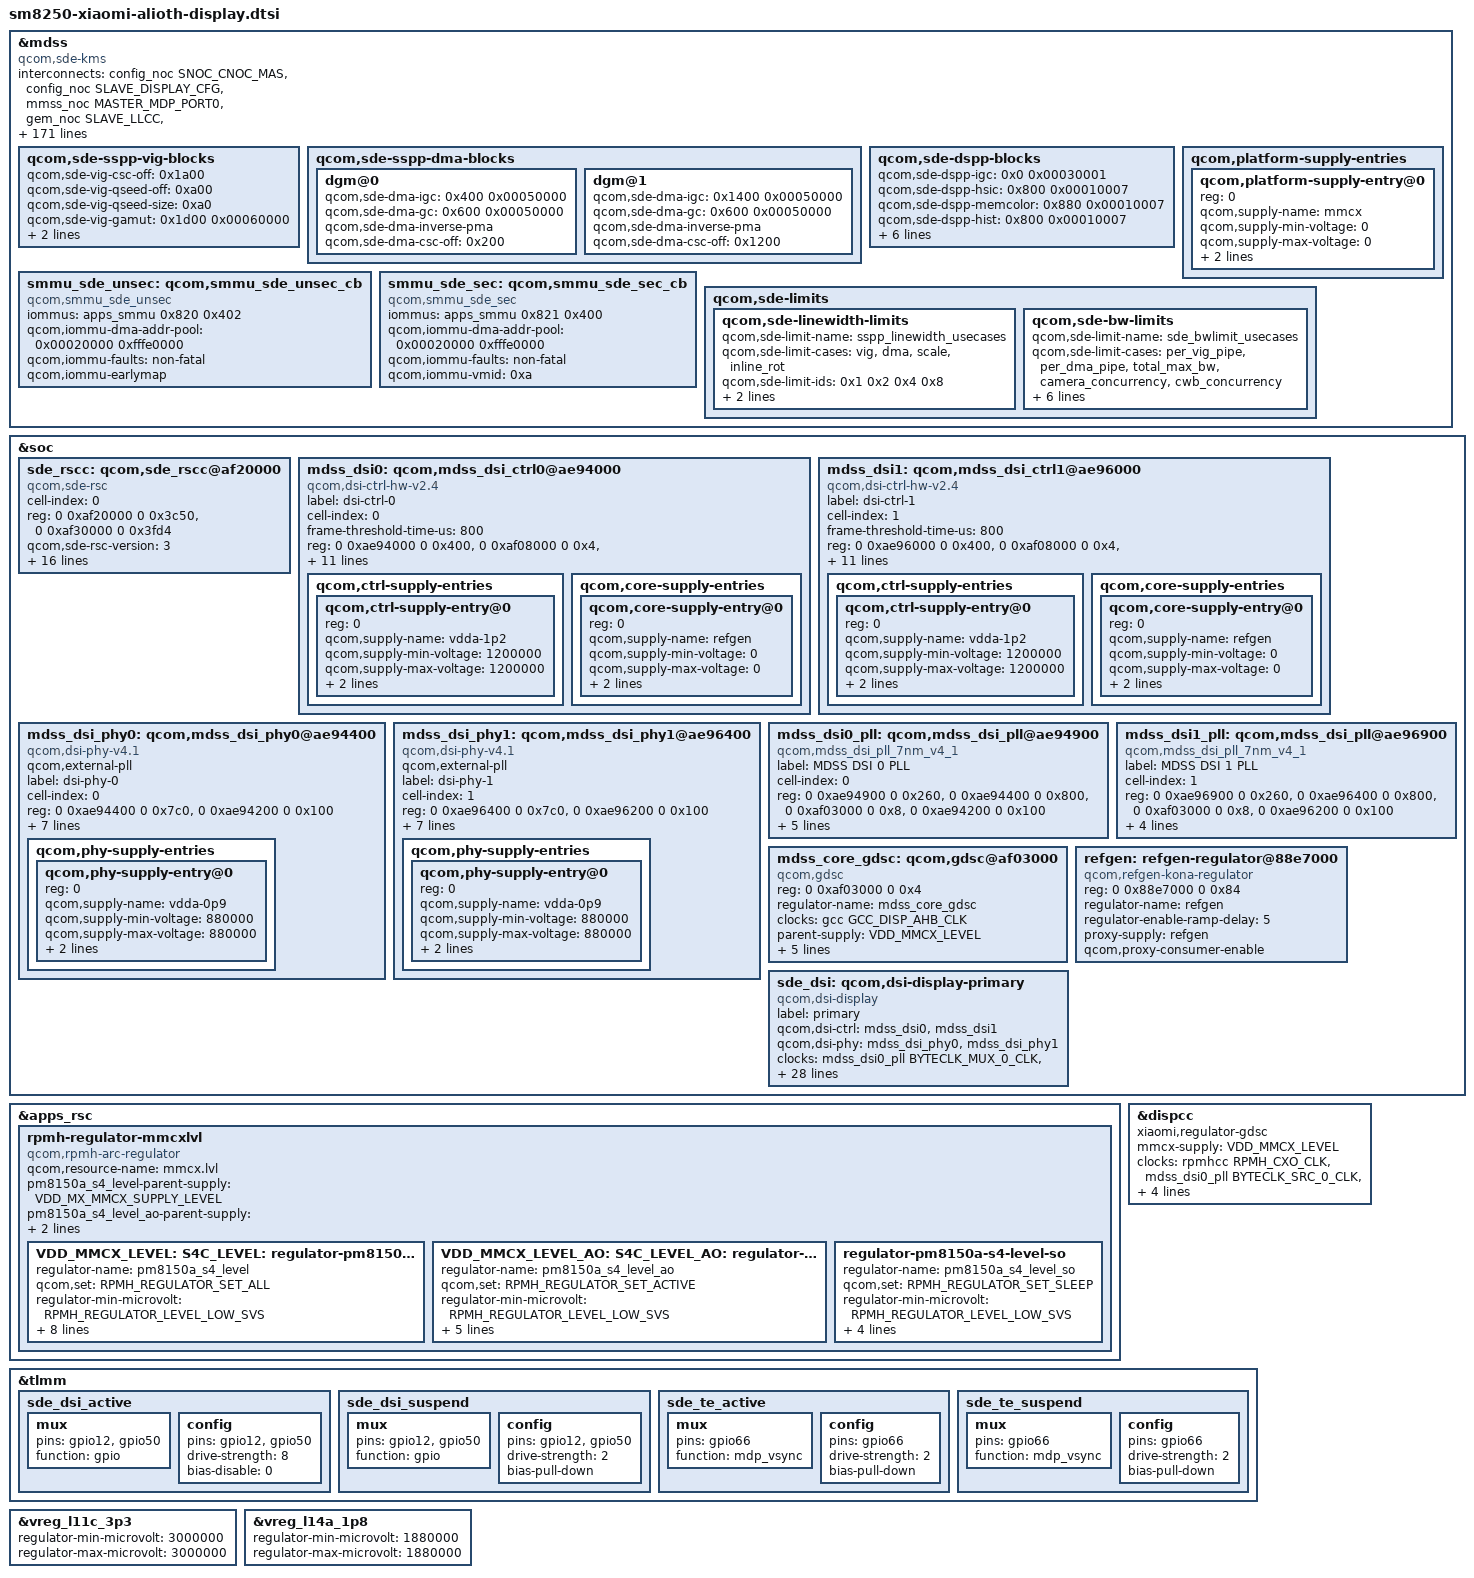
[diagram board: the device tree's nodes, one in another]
// SPDX-License-Identifier: GPL-2.0-only
/* Donor SDE catalog, translated native clocks and interconnect providers. */
#include <dt-bindings/clock/mdss-7nm-pll-clk.h>
#include <dt-bindings/interconnect/qcom,sm8250.h>


&mdss {
 /delete-property/ power-domains;
 status = "okay";

 interconnects = <&config_noc SNOC_CNOC_MAS &config_noc SLAVE_DISPLAY_CFG>,
  <&mmss_noc MASTER_MDP_PORT0 &gem_noc SLAVE_LLCC>,
  <&mmss_noc MASTER_MDP_PORT1 &gem_noc SLAVE_LLCC>,
  <&gem_noc MASTER_MNOC_HF_MEM_NOC &gem_noc SLAVE_LLCC>,
  <&mc_virt MASTER_LLCC &mc_virt SLAVE_EBI_CH0>;
 interconnect-names = "qcom,sde-reg-bus", "qcom,sde-data-bus0",
  "qcom,sde-data-bus1", "qcom,sde-llcc-bus", "qcom,sde-ebi-bus";
 qcom,sde-reg-bus,vectors-KBps = <0 0>, <0 76800>, <0 150000>, <0 300000>;
 connectors = <&sde_dsi &sde_rscc>;

};

&mdss {
 /delete-node/ mdp@ae01000;
 /delete-node/ dsi@ae94000;
 /delete-node/ dsi@ae96000;
 /delete-node/ dsi-phy@ae94400;
 /delete-node/ dsi-phy@ae96400;
};

&mdss {

		compatible = "qcom,sde-kms";
		reg = <0 0x0ae00000 0 0x84208>,
		      <0 0x0aeb0000 0 0x2008>,
		      <0 0x0aeac000 0 0x214>,
		      <0 0x0ae8f000 0 0x02c>,
		      <0 0x0af50000 0 0x038>;
		reg-names = "mdp_phys",
			"vbif_phys",
			"regdma_phys",
			"sid_phys",
			"swfuse_phys";

		clocks =
			<&gcc GCC_DISP_AHB_CLK>,
			<&gcc GCC_DISP_HF_AXI_CLK>,
			<&gcc GCC_DISP_SF_AXI_CLK>,
			<&dispcc DISP_CC_MDSS_AHB_CLK>,
			<&dispcc DISP_CC_MDSS_MDP_CLK>,
			<&dispcc DISP_CC_MDSS_VSYNC_CLK>,
			<&dispcc DISP_CC_MDSS_MDP_LUT_CLK>,
			<&dispcc DISP_CC_MDSS_ROT_CLK>;
		clock-names = "gcc_iface", "gcc_bus", "gcc_nrt_bus",
				"iface_clk", "core_clk", "vsync_clk",
				"lut_clk", "rot_clk";
		clock-rate = <0 0 0 0 300000000 19200000 300000000 19200000>;
		clock-max-rate = <0 0 0 0 460000000 19200000 460000000
					460000000>;

		mmcx-supply = <&VDD_MMCX_LEVEL>;

		/* interrupt config */
		interrupts = <GIC_SPI 83 IRQ_TYPE_LEVEL_HIGH>;
		interrupt-controller;
		#interrupt-cells = <1>;

		#power-domain-cells = <0>;

		/* hw blocks */
		qcom,sde-off = <0x1000>;
		qcom,sde-len = <0x494>;

		qcom,sde-ctl-off = <0x2000 0x2200 0x2400
				     0x2600 0x2800 0x2a00>;
		qcom,sde-ctl-size = <0x1dc>;
		qcom,sde-ctl-display-pref = "primary", "none", "none",
			    "none", "none";

		qcom,sde-mixer-off = <0x45000 0x46000 0x47000
				      0x48000 0x49000 0x4a000>;
		qcom,sde-mixer-size = <0x320>;
		qcom,sde-mixer-display-pref = "primary", "primary", "none",
					      "none", "none", "none";

		qcom,sde-mixer-cwb-pref = "none", "none", "cwb",
					      "cwb", "cwb", "cwb";

		qcom,sde-dspp-top-off = <0x1300>;
		qcom,sde-dspp-top-size = <0x80>;
		qcom,sde-dspp-off = <0x55000 0x57000 0x59000 0x5b000>;
		qcom,sde-dspp-size = <0x1800>;

		qcom,sde-dest-scaler-top-off = <0x00061000>;
		qcom,sde-dest-scaler-top-size = <0x1c>;
		qcom,sde-dest-scaler-off = <0x800 0x1000>;
		qcom,sde-dest-scaler-size = <0x800>;

		qcom,sde-wb-off = <0x66000>;
		qcom,sde-wb-size = <0x2c8>;
		qcom,sde-wb-xin-id = <6>;
		qcom,sde-wb-id = <2>;
		qcom,sde-wb-clk-ctrl = <0x2bc 16>;
		qcom,sde-wb-clk-status = <0x3bc 20>;

		qcom,sde-intf-off = <0x6b000 0x6b800
					0x6c000 0x6c800>;
		qcom,sde-intf-size = <0x2b8>;
		qcom,sde-intf-type = "dp", "dsi", "dsi", "dp";

		qcom,sde-pp-off = <0x71000 0x71800
					  0x72000 0x72800 0x73000 0x73800>;
		qcom,sde-pp-slave = <0x0 0x0 0x0 0x0 0x0 0x0>;
		qcom,sde-pp-size = <0xd4>;
		qcom,sde-pp-merge-3d-id = <0x0 0x0 0x1 0x1 0x2 0x2>;

		qcom,sde-merge-3d-off = <0x84000 0x84100 0x84200>;
		qcom,sde-merge-3d-size = <0x100>;

		qcom,sde-te2-off = <0x2000 0x2000 0x0 0x0 0x0 0x0>;

		qcom,sde-cdm-off = <0x7a200>;
		qcom,sde-cdm-size = <0x224>;

		qcom,sde-dsc-off = <0x81000 0x81400 0x81800 0x81c00>;
		qcom,sde-dsc-size = <0x140>;
		qcom,sde-dsc-pair-mask = <2 1 4 3>;
		qcom,sde-dsc-linewidth = <2048>;

		qcom,sde-dither-off = <0x30e0 0x30e0 0x30e0
							0x30e0 0x30e0 0x30e0>;
		qcom,sde-dither-version = <0x00010000>;
		qcom,sde-dither-size = <0x20>;

		qcom,sde-sspp-type = "vig", "vig", "vig", "vig",
					"dma", "dma", "dma", "dma";

		qcom,sde-sspp-off = <0x5000 0x7000 0x9000 0xb000
					0x25000 0x27000 0x29000 0x2b000>;
		qcom,sde-sspp-src-size = <0x1f8>;

		qcom,sde-sspp-xin-id = <0 4 8 12
					1 5 9 13>;
		qcom,sde-sspp-excl-rect = <1 1 1 1
						1 1 1 1>;
		qcom,sde-sspp-smart-dma-priority = <5 6 7 8 1 2 3 4>;
		qcom,sde-smart-dma-rev = "smart_dma_v2p5";

		qcom,sde-mixer-pair-mask = <2 1 4 3 6 5>;

		qcom,sde-mixer-blend-op-off = <0x20 0x38 0x50 0x68 0x80 0x98
						0xb0 0xc8 0xe0 0xf8 0x110>;

		qcom,sde-max-per-pipe-bw-kbps = <4400000 4400000
						 4400000 4400000
						 4400000 4400000
						 4400000 4400000>;

		qcom,sde-max-per-pipe-bw-high-kbps = <5300000 5300000
						      5300000 5300000
						      5300000 5300000
						      5300000 5300000>;

		/* offsets are relative to "mdp_phys + qcom,sde-off */
		qcom,sde-sspp-clk-ctrl =
				<0x2ac 0>, <0x2b4 0>, <0x2bc 0>, <0x2c4 0>,
				 <0x2ac 8>, <0x2b4 8>, <0x2bc 8>, <0x2c4 8>;
		qcom,sde-sspp-csc-off = <0x1a00>;
		qcom,sde-csc-type = "csc-10bit";
		qcom,sde-qseed-type = "qseedv3lite";
		qcom,sde-sspp-qseed-off = <0xa00>;
		qcom,sde-mixer-linewidth = <2560>;
		qcom,sde-sspp-linewidth = <4096>;
		qcom,sde-wb-linewidth = <4096>;
		qcom,sde-mixer-blendstages = <0xb>;
		qcom,sde-highest-bank-bit = <0x3>;
		qcom,sde-ubwc-version = <0x400>;
		qcom,sde-ubwc-swizzle = <0x6>;
		qcom,sde-ubwc-bw-calc-version = <0x1>;
		qcom,sde-ubwc-static = <0x1>;
		qcom,sde-macrotile-mode = <0x1>;
		qcom,sde-smart-panel-align-mode = <0xc>;
		qcom,sde-panic-per-pipe;
		qcom,sde-has-cdp;
		qcom,sde-has-src-split;
		qcom,sde-pipe-order-version = <0x1>;
		qcom,sde-has-dim-layer;
		qcom,sde-has-dest-scaler;
		qcom,sde-has-idle-pc;
		qcom,sde-max-dest-scaler-input-linewidth = <2048>;
		qcom,sde-max-dest-scaler-output-linewidth = <2560>;
		qcom,sde-max-bw-low-kbps = <13700000>;
		qcom,sde-max-bw-high-kbps = <16600000>;
		qcom,sde-min-core-ib-kbps = <4800000>;
		qcom,sde-min-llcc-ib-kbps = <0>;
		qcom,sde-min-dram-ib-kbps = <800000>;
		qcom,sde-dram-channels = <2>;
		qcom,sde-num-nrt-paths = <0>;
		qcom,sde-dspp-ltm-version = <0x00010000>;
		/* offsets are based off dspp 0 and dspp 1 */
		qcom,sde-dspp-ltm-off = <0x2a000 0x28100>;

		qcom,sde-uidle-off = <0x80000>;
		qcom,sde-uidle-size = <0x70>;

		qcom,sde-vbif-off = <0>;
		qcom,sde-vbif-size = <0x1040>;
		qcom,sde-vbif-id = <0>;
		qcom,sde-vbif-memtype-0 = <3 3 3 3 3 3 3 3>;
		qcom,sde-vbif-memtype-1 = <3 3 3 3 3 3>;

		qcom,sde-vbif-qos-rt-remap = <3 3 4 4 5 5 6 6>;
		qcom,sde-vbif-qos-nrt-remap = <3 3 3 3 3 3 3 3>;
		qcom,sde-vbif-qos-cwb-remap = <3 3 4 4 5 5 6 3>;
		qcom,sde-vbif-qos-lutdma-remap = <3 3 3 3 4 4 4 4>;

		/* macrotile & macrotile-qseed has the same configs */
		qcom,sde-danger-lut = <0x000000ff 0x0000ffff
			0x00000000 0x00000000 0x0000ffff>;

		qcom,sde-safe-lut-linear = <0 0xfff0>;
		qcom,sde-safe-lut-macrotile = <0 0xff00>;
		/* same as safe-lut-macrotile */
		qcom,sde-safe-lut-macrotile-qseed = <0 0xff00>;
		qcom,sde-safe-lut-nrt = <0 0xffff>;
		qcom,sde-safe-lut-cwb = <0 0x3ff>;

		qcom,sde-qos-lut-linear = <0 0x00112222 0x22335777>;
		qcom,sde-qos-lut-macrotile = <0 0x00112233 0x44556677>;
		qcom,sde-qos-lut-macrotile-qseed = <0 0x00112233 0x66777777>;
		qcom,sde-qos-lut-nrt = <0 0x00000000 0x00000000>;
		qcom,sde-qos-lut-cwb = <0 0x66666541 0x00000000>;

		qcom,sde-cdp-setting = <1 1>, <1 0>;

		qcom,sde-qos-cpu-mask = <0x3>;
		qcom,sde-qos-cpu-dma-latency = <300>;
		qcom,sde-qos-cpu-irq-latency = <300>;

		/* offsets are relative to "mdp_phys + qcom,sde-off */

		qcom,sde-reg-dma-off = <0>;
		qcom,sde-reg-dma-version = <0x00010002>;
		qcom,sde-reg-dma-trigger-off = <0x119c>;
		qcom,sde-reg-dma-xin-id = <7>;
		qcom,sde-reg-dma-clk-ctrl = <0x2bc 20>;

		qcom,sde-secure-sid-mask = <0x4000821>;

		qcom,sde-sspp-vig-blocks {
			qcom,sde-vig-csc-off = <0x1a00>;
			qcom,sde-vig-qseed-off = <0xa00>;
			qcom,sde-vig-qseed-size = <0xa0>;
			qcom,sde-vig-gamut = <0x1d00 0x00060000>;
			qcom,sde-vig-igc = <0x1d00 0x00060000>;
			qcom,sde-vig-inverse-pma;
		};

		qcom,sde-sspp-dma-blocks {
			dgm@0 {
				qcom,sde-dma-igc = <0x400 0x00050000>;
				qcom,sde-dma-gc = <0x600 0x00050000>;
				qcom,sde-dma-inverse-pma;
				qcom,sde-dma-csc-off = <0x200>;
			};

			dgm@1 {
				qcom,sde-dma-igc = <0x1400 0x00050000>;
				qcom,sde-dma-gc = <0x600 0x00050000>;
				qcom,sde-dma-inverse-pma;
				qcom,sde-dma-csc-off = <0x1200>;
			};
		};

		qcom,sde-dspp-blocks {
			qcom,sde-dspp-igc = <0x0 0x00030001>;
			qcom,sde-dspp-hsic = <0x800 0x00010007>;
			qcom,sde-dspp-memcolor = <0x880 0x00010007>;
			qcom,sde-dspp-hist = <0x800 0x00010007>;
			qcom,sde-dspp-sixzone= <0x900 0x00010007>;
			qcom,sde-dspp-vlut = <0xa00 0x00010008>;
			qcom,sde-dspp-gamut = <0x1000 0x00040002>;
			qcom,sde-dspp-pcc = <0x1700 0x00040000>;
			qcom,sde-dspp-gc = <0x17c0 0x00010008>;
			qcom,sde-dspp-dither = <0x82c 0x00010007>;
		};

		qcom,platform-supply-entries {
			#address-cells = <1>;
			#size-cells = <0>;

			qcom,platform-supply-entry@0 {
				reg = <0>;
				qcom,supply-name = "mmcx";
				qcom,supply-min-voltage = <0>;
				qcom,supply-max-voltage = <0>;
				qcom,supply-enable-load = <0>;
				qcom,supply-disable-load = <0>;
			};
		};

		smmu_sde_unsec: qcom,smmu_sde_unsec_cb {
			compatible = "qcom,smmu_sde_unsec";
			iommus = <&apps_smmu 0x820 0x402>;
			qcom,iommu-dma-addr-pool = <0x00020000 0xfffe0000>;
			qcom,iommu-faults = "non-fatal";
			qcom,iommu-earlymap; /* for cont-splash */
		};

		smmu_sde_sec: qcom,smmu_sde_sec_cb {
			compatible = "qcom,smmu_sde_sec";
			iommus = <&apps_smmu 0x821 0x400>;
			qcom,iommu-dma-addr-pool = <0x00020000 0xfffe0000>;
			qcom,iommu-faults = "non-fatal";
			qcom,iommu-vmid = <0xa>;
		};

		/* data and reg bus scale settings */
		

		
		qcom,sde-limits {
			qcom,sde-linewidth-limits {
				qcom,sde-limit-name = "sspp_linewidth_usecases";
				qcom,sde-limit-cases = "vig", "dma", "scale", "inline_rot";
				qcom,sde-limit-ids= <0x1 0x2 0x4 0x8>;
				qcom,sde-limit-values = <0x1 4096>,
							<0x5 2560>,
							<0x2 4096>,
							<0x9 1088>;
			};

			qcom,sde-bw-limits {
				qcom,sde-limit-name = "sde_bwlimit_usecases";
				qcom,sde-limit-cases = "per_vig_pipe",
							"per_dma_pipe",
							"total_max_bw",
							"camera_concurrency",
							"cwb_concurrency";
				qcom,sde-limit-ids = <0x1 0x2 0x4 0x8 0x10>;
				qcom,sde-limit-values = <0x1 5300000>,
							<0x11 5300000>,
							<0x9 4400000>,
							<0x19 4400000>,
							<0x2 5300000>,
							<0x12 5300000>,
							<0xa 4400000>,
							<0x1a 4400000>,
							<0x4 16600000>,
							<0x14 16600000>,
							<0xc 13700000>,
							<0x1c 13700000>;
			};
		};
	
};

&soc {
sde_rscc: qcom,sde_rscc@af20000 {
		cell-index = <0>;
		compatible = "qcom,sde-rsc";
		reg = <0 0xaf20000 0 0x3c50>,
			<0 0xaf30000 0 0x3fd4>;
		reg-names = "drv", "wrapper";
		qcom,sde-rsc-version = <3>;

		qcom,sde-dram-channels = <2>;

		vdd-supply = <&mdss_core_gdsc>;
		clocks = <&dispcc DISP_CC_MDSS_RSCC_VSYNC_CLK>,
			<&dispcc DISP_CC_MDSS_NON_GDSC_AHB_CLK>,
			<&dispcc DISP_CC_MDSS_RSCC_AHB_CLK>;
		clock-names = "vsync_clk", "gdsc_clk", "iface_clk";

		/* data and reg bus scale settings */
		

		

		
	
 interconnects = <&config_noc SNOC_CNOC_MAS &config_noc SLAVE_DISPLAY_CFG>,
  <&mmss_noc MASTER_MDP_PORT0 &gem_noc SLAVE_LLCC>,
  <&mmss_noc MASTER_MDP_PORT1 &gem_noc SLAVE_LLCC>,
  <&gem_noc MASTER_MNOC_HF_MEM_NOC &gem_noc SLAVE_LLCC>,
  <&mc_virt MASTER_LLCC &mc_virt SLAVE_EBI_CH0>;
 interconnect-names = "qcom,sde-reg-bus", "qcom,sde-data-bus0",
  "qcom,sde-data-bus1", "qcom,sde-llcc-bus", "qcom,sde-ebi-bus";
 qcom,sde-reg-bus,vectors-KBps = <0 0>, <0 76800>, <0 150000>, <0 300000>;
};
mdss_dsi0: qcom,mdss_dsi_ctrl0@ae94000 {
		compatible = "qcom,dsi-ctrl-hw-v2.4";
		label = "dsi-ctrl-0";
		cell-index = <0>;
		frame-threshold-time-us = <800>;
		reg = <0 0xae94000 0 0x400>,
			<0 0xaf08000 0 0x4>,
			<0 0x0ae6b800 0 0x300>;
		reg-names = "dsi_ctrl", "disp_cc_base", "mdp_intf_base";
		interrupt-parent = <&mdss>;
		interrupts = <4>;
		vdda-1p2-supply = <&vreg_l9a_1p2>;
		refgen-supply = <&refgen>;
		clocks = <&dispcc DISP_CC_MDSS_BYTE0_CLK>,
			<&dispcc DISP_CC_MDSS_BYTE0_CLK_SRC>,
			<&dispcc DISP_CC_MDSS_BYTE0_INTF_CLK>,
			<&dispcc DISP_CC_MDSS_PCLK0_CLK>,
			<&dispcc DISP_CC_MDSS_PCLK0_CLK_SRC>,
			<&dispcc DISP_CC_MDSS_ESC0_CLK>;
		clock-names = "byte_clk", "byte_clk_rcg", "byte_intf_clk",
				"pixel_clk", "pixel_clk_rcg", "esc_clk";

		qcom,ctrl-supply-entries {
			#address-cells = <1>;
			#size-cells = <0>;

			qcom,ctrl-supply-entry@0 {
				reg = <0>;
				qcom,supply-name = "vdda-1p2";
				qcom,supply-min-voltage = <1200000>;
				qcom,supply-max-voltage = <1200000>;
				qcom,supply-enable-load = <26700>;
				qcom,supply-disable-load = <0>;
			};
		};

		qcom,core-supply-entries {
			#address-cells = <1>;
			#size-cells = <0>;

			qcom,core-supply-entry@0 {
				reg = <0>;
				qcom,supply-name = "refgen";
				qcom,supply-min-voltage = <0>;
				qcom,supply-max-voltage = <0>;
				qcom,supply-enable-load = <0>;
				qcom,supply-disable-load = <0>;
			};
		};
	};
mdss_dsi1: qcom,mdss_dsi_ctrl1@ae96000 {
		compatible = "qcom,dsi-ctrl-hw-v2.4";
		label = "dsi-ctrl-1";
		cell-index = <1>;
		frame-threshold-time-us = <800>;
		reg = <0 0xae96000 0 0x400>,
			<0 0xaf08000 0 0x4>,
			<0 0x0ae6c000 0 0x300>;
		reg-names = "dsi_ctrl", "disp_cc_base", "mdp_intf_base";
		interrupt-parent = <&mdss>;
		interrupts = <5>;
		vdda-1p2-supply = <&vreg_l9a_1p2>;
		refgen-supply = <&refgen>;
		clocks = <&dispcc DISP_CC_MDSS_BYTE1_CLK>,
			<&dispcc DISP_CC_MDSS_BYTE1_CLK_SRC>,
			<&dispcc DISP_CC_MDSS_BYTE1_INTF_CLK>,
			<&dispcc DISP_CC_MDSS_PCLK1_CLK>,
			<&dispcc DISP_CC_MDSS_PCLK1_CLK_SRC>,
			<&dispcc DISP_CC_MDSS_ESC1_CLK>;
		clock-names = "byte_clk", "byte_clk_rcg", "byte_intf_clk",
				"pixel_clk", "pixel_clk_rcg", "esc_clk";
		qcom,ctrl-supply-entries {
			#address-cells = <1>;
			#size-cells = <0>;

			qcom,ctrl-supply-entry@0 {
				reg = <0>;
				qcom,supply-name = "vdda-1p2";
				qcom,supply-min-voltage = <1200000>;
				qcom,supply-max-voltage = <1200000>;
				qcom,supply-enable-load = <26700>;
				qcom,supply-disable-load = <0>;
			};
		};

		qcom,core-supply-entries {
			#address-cells = <1>;
			#size-cells = <0>;

			qcom,core-supply-entry@0 {
				reg = <0>;
				qcom,supply-name = "refgen";
				qcom,supply-min-voltage = <0>;
				qcom,supply-max-voltage = <0>;
				qcom,supply-enable-load = <0>;
				qcom,supply-disable-load = <0>;
			};
		};
	};
mdss_dsi_phy0: qcom,mdss_dsi_phy0@ae94400 {
		qcom,external-pll;
		compatible = "qcom,dsi-phy-v4.1";
		label = "dsi-phy-0";
		cell-index = <0>;
		reg = <0 0xae94400 0 0x7c0>,
			<0 0xae94200 0 0x100>;
		reg-names = "dsi_phy", "dyn_refresh_base";
		vdda-0p9-supply = <&vreg_l5a_0p875>;
		qcom,platform-strength-ctrl = [55 03
						55 03
						55 03
						55 03
						55 00];
		qcom,platform-lane-config = [00 00 0a 0a
						00 00 0a 0a
						00 00 0a 0a
						00 00 0a 0a
						00 00 8a 8a];
		qcom,platform-regulator-settings = [1d 1d 1d 1d 1d];
		qcom,phy-supply-entries {
			#address-cells = <1>;
			#size-cells = <0>;
			qcom,phy-supply-entry@0 {
				reg = <0>;
				qcom,supply-name = "vdda-0p9";
				qcom,supply-min-voltage = <880000>;
				qcom,supply-max-voltage = <880000>;
				qcom,supply-enable-load = <46000>;
				qcom,supply-disable-load = <0>;
			};
		};
	};
mdss_dsi_phy1: qcom,mdss_dsi_phy1@ae96400 {
		qcom,external-pll;
		compatible = "qcom,dsi-phy-v4.1";
		label = "dsi-phy-1";
		cell-index = <1>;
		reg = <0 0xae96400 0 0x7c0>,
			<0 0xae96200 0 0x100>;
		reg-names = "dsi_phy", "dyn_refresh_base";
		vdda-0p9-supply = <&vreg_l5a_0p875>;
		qcom,platform-strength-ctrl = [55 03
						55 03
						55 03
						55 03
						55 00];
		qcom,platform-regulator-settings = [1d 1d 1d 1d 1d];
		qcom,platform-lane-config = [00 00 0a 0a
						00 00 0a 0a
						00 00 0a 0a
						00 00 0a 0a
						00 00 8a 8a];
		qcom,phy-supply-entries {
			#address-cells = <1>;
			#size-cells = <0>;
			qcom,phy-supply-entry@0 {
				reg = <0>;
				qcom,supply-name = "vdda-0p9";
				qcom,supply-min-voltage = <880000>;
				qcom,supply-max-voltage = <880000>;
				qcom,supply-enable-load = <46000>;
				qcom,supply-disable-load = <0>;
			};
		};
	};
mdss_dsi0_pll: qcom,mdss_dsi_pll@ae94900 {
		compatible = "qcom,mdss_dsi_pll_7nm_v4_1";
		label = "MDSS DSI 0 PLL";
		cell-index = <0>;
		#clock-cells = <1>;
		reg = <0 0xae94900 0 0x260>,
		      <0 0xae94400 0 0x800>,
		      <0 0xaf03000 0 0x8>,
		      <0 0xae94200 0 0x100>;
		reg-names = "pll_base", "phy_base", "gdsc_base",
				"dynamic_pll_base";
		clocks = <&dispcc DISP_CC_MDSS_AHB_CLK>;
		clock-names = "iface_clk";
		clock-rate = <0>;
		memory-region = <&dfps_data_mem>;
		qcom,dsi-pll-ssc-en;
		qcom,dsi-pll-ssc-mode = "down-spread";
	};
mdss_dsi1_pll: qcom,mdss_dsi_pll@ae96900 {
		compatible = "qcom,mdss_dsi_pll_7nm_v4_1";
		label = "MDSS DSI 1 PLL";
		cell-index = <1>;
		#clock-cells = <1>;
		reg = <0 0xae96900 0 0x260>,
		      <0 0xae96400 0 0x800>,
		      <0 0xaf03000 0 0x8>,
		      <0 0xae96200 0 0x100>;
		reg-names = "pll_base", "phy_base", "gdsc_base",
				"dynamic_pll_base";
		clocks = <&dispcc DISP_CC_MDSS_AHB_CLK>;
		clock-names = "iface_clk";
		clock-rate = <0>;
		qcom,dsi-pll-ssc-en;
		qcom,dsi-pll-ssc-mode = "down-spread";
	};
mdss_core_gdsc: qcom,gdsc@af03000 {
		compatible = "qcom,gdsc";
		reg = <0 0xaf03000 0 0x4>;
		regulator-name = "mdss_core_gdsc";
		clock-names = "ahb_clk";
		clocks = <&gcc GCC_DISP_AHB_CLK>;
		parent-supply = <&VDD_MMCX_LEVEL>;
		vdd_parent-supply = <&VDD_MMCX_LEVEL>;




		qcom,support-hw-trigger;
		qcom,retain-regs;
		proxy-supply = <&mdss_core_gdsc>;
		qcom,proxy-consumer-enable;
	};
refgen: refgen-regulator@88e7000 {
		compatible = "qcom,refgen-kona-regulator";
		reg = <0 0x88e7000 0 0x84>;
		regulator-name = "refgen";
		regulator-enable-ramp-delay = <5>;
		proxy-supply = <&refgen>;
		qcom,proxy-consumer-enable;
	};
sde_dsi: qcom,dsi-display-primary {
		compatible = "qcom,dsi-display";
		label = "primary";

		qcom,dsi-ctrl = <&mdss_dsi0 &mdss_dsi1>;
		qcom,dsi-phy = <&mdss_dsi_phy0 &mdss_dsi_phy1>;

		clocks = <&mdss_dsi0_pll BYTECLK_MUX_0_CLK>,
			 <&mdss_dsi0_pll PCLK_MUX_0_CLK>,
			 <&mdss_dsi0_pll BYTECLK_SRC_0_CLK>,
			 <&mdss_dsi0_pll PCLK_SRC_0_CLK>,
			 <&mdss_dsi0_pll CPHY_BYTECLK_SRC_0_CLK>,
			 <&mdss_dsi0_pll CPHY_PCLK_SRC_0_CLK>,
			 <&mdss_dsi0_pll SHADOW_BYTECLK_SRC_0_CLK>,
			 <&mdss_dsi0_pll SHADOW_PCLK_SRC_0_CLK>,
			 <&mdss_dsi0_pll SHADOW_CPHY_BYTECLK_SRC_0_CLK>,
			 <&mdss_dsi0_pll SHADOW_CPHY_PCLK_SRC_0_CLK>,
			 <&mdss_dsi1_pll BYTECLK_MUX_1_CLK>,
			 <&mdss_dsi1_pll PCLK_MUX_1_CLK>,
			 <&mdss_dsi1_pll BYTECLK_SRC_1_CLK>,
			 <&mdss_dsi1_pll PCLK_SRC_1_CLK>,
			 <&mdss_dsi1_pll CPHY_BYTECLK_SRC_1_CLK>,
			 <&mdss_dsi1_pll CPHY_PCLK_SRC_1_CLK>,
			 <&mdss_dsi1_pll SHADOW_BYTECLK_SRC_1_CLK>,
			 <&mdss_dsi1_pll SHADOW_PCLK_SRC_1_CLK>,
			 <&mdss_dsi1_pll SHADOW_CPHY_BYTECLK_SRC_1_CLK>,
			 <&mdss_dsi1_pll SHADOW_CPHY_PCLK_SRC_1_CLK>;

		clock-names = "mux_byte_clk0", "mux_pixel_clk0",
				"src_byte_clk0", "src_pixel_clk0",
				"cphy_byte_clk0", "cphy_pixel_clk0",
				"shadow_byte_clk0", "shadow_pixel_clk0",
				"shadow_cphybyte_clk0", "shadow_cphypixel_clk0",
				"mux_byte_clk1", "mux_pixel_clk1",
				"src_byte_clk1", "src_pixel_clk1",
				"cphy_byte_clk1", "cphy_pixel_clk1",
				"shadow_byte_clk1", "shadow_pixel_clk1",
				"shadow_cphybyte_clk1", "shadow_cphypixel_clk1";

		pinctrl-names = "panel_active", "panel_suspend";
		pinctrl-0 = <&sde_dsi_active &sde_te_active>;
		pinctrl-1 = <&sde_dsi_suspend &sde_te_suspend>;

		qcom,platform-te-gpio = <&tlmm 66 0>;
		qcom,panel-te-source = <0>;

		vddio-supply = <&vreg_l14a_1p8>;
		vci-supply = <&vreg_l11c_3p3>;

		qcom,mdp = <&mdss>;
		qcom,dsi-default-panel = <&dsi_k11a_38_08_0a_dsc_cmd>;
	};
};

&apps_rsc {
rpmh-regulator-mmcxlvl {
		compatible = "qcom,rpmh-arc-regulator";
		qcom,resource-name = "mmcx.lvl";
		pm8150a_s4_level-parent-supply = <&VDD_MX_MMCX_SUPPLY_LEVEL>;
		pm8150a_s4_level_ao-parent-supply = <&VDD_MX_LEVEL_AO>;
		proxy-supply = <&VDD_MMCX_LEVEL>;

		VDD_MMCX_LEVEL: S4C_LEVEL:
		pm8150a_s4_level: regulator-pm8150a-s4-level {
			regulator-name = "pm8150a_s4_level";
			qcom,set = <RPMH_REGULATOR_SET_ALL>;
			regulator-min-microvolt
				= <RPMH_REGULATOR_LEVEL_LOW_SVS>;
			regulator-max-microvolt
				= <RPMH_REGULATOR_LEVEL_MAX>;
			qcom,init-voltage-level
				= <RPMH_REGULATOR_LEVEL_LOW_SVS>;
			qcom,min-dropout-voltage-level = <(-1)>;
			qcom,proxy-consumer-enable;
			qcom,proxy-consumer-voltage
				= <RPMH_REGULATOR_LEVEL_TURBO
				   RPMH_REGULATOR_LEVEL_MAX>;
		};

		VDD_MMCX_LEVEL_AO: S4C_LEVEL_AO:
		pm8150a_s4_level_ao: regulator-pm8150a-s4-level-ao {
			regulator-name = "pm8150a_s4_level_ao";
			qcom,set = <RPMH_REGULATOR_SET_ACTIVE>;
			regulator-min-microvolt
				= <RPMH_REGULATOR_LEVEL_LOW_SVS>;
			regulator-max-microvolt
				= <RPMH_REGULATOR_LEVEL_MAX>;
			qcom,init-voltage-level
				= <RPMH_REGULATOR_LEVEL_LOW_SVS>;
			qcom,min-dropout-voltage-level = <(-1)>;
		};

		regulator-pm8150a-s4-level-so {
			regulator-name = "pm8150a_s4_level_so";
			qcom,set = <RPMH_REGULATOR_SET_SLEEP>;
			regulator-min-microvolt
				= <RPMH_REGULATOR_LEVEL_LOW_SVS>;
			regulator-max-microvolt
				= <RPMH_REGULATOR_LEVEL_MAX>;
			qcom,init-voltage-level
				= <RPMH_REGULATOR_LEVEL_LOW_SVS>;
		};
	};
};

&dispcc {
 xiaomi,regulator-gdsc;
 /delete-property/ #power-domain-cells;
 mmcx-supply = <&VDD_MMCX_LEVEL>;
 clocks = <&rpmhcc RPMH_CXO_CLK>,
  <&mdss_dsi0_pll BYTECLK_SRC_0_CLK>, <&mdss_dsi0_pll PCLK_SRC_0_CLK>,
  <&mdss_dsi1_pll BYTECLK_SRC_1_CLK>, <&mdss_dsi1_pll PCLK_SRC_1_CLK>,
  <&dp_phy 0>, <&dp_phy 1>;
};

&tlmm {
sde_dsi_active: sde_dsi_active {
				mux {
					pins = "gpio12", "gpio50";
					function = "gpio";
				};

				config {
					pins = "gpio12", "gpio50";
					drive-strength = <8>;   /* 8 mA */
					bias-disable = <0>;   /* no pull */
				};
			};
sde_dsi_suspend: sde_dsi_suspend {
				mux {
					pins = "gpio12", "gpio50";
					function = "gpio";
				};

				config {
					pins = "gpio12", "gpio50";
					drive-strength = <2>;   /* 2 mA */
					bias-pull-down;         /* PULL DOWN */
				};
			};
sde_te_active: sde_te_active {
				mux {
					pins = "gpio66";
					function = "mdp_vsync";
				};

				config {
					pins = "gpio66";
					drive-strength = <2>;   /* 2 mA */
					bias-pull-down;         /* PULL DOWN */
				};
			};
sde_te_suspend: sde_te_suspend {
				mux {
					pins = "gpio66";
					function = "mdp_vsync";
				};

				config {
					pins = "gpio66";
					drive-strength = <2>;   /* 2 mA */
					bias-pull-down;         /* PULL DOWN */
				};
			};
};

&vreg_l11c_3p3 {
 regulator-min-microvolt = <3000000>;
 regulator-max-microvolt = <3000000>;
};
&vreg_l14a_1p8 {
 regulator-min-microvolt = <1880000>;
 regulator-max-microvolt = <1880000>;
};
